# IMM100A register map
Vendor: Infineon; File version: 0.8.0 (Reference Manual v0.8.0)
CPU: CM0 r0p0, little endian, no MPU, no FPU, 2 interrupt priority bits
Registers are 32-bit, read-write, reset 0x0 unless marked. A register's access mark holds for its fields unless they carry their own. Offsets are from the block's base; [hi:lo] are bit positions; lines under a group give offsets from that group; {n}, {i} and the like mark numbered series; 'fields as' and 'values as' point back to an identical list.

## VADC — Analog to Digital Converter
Base 0x48030000
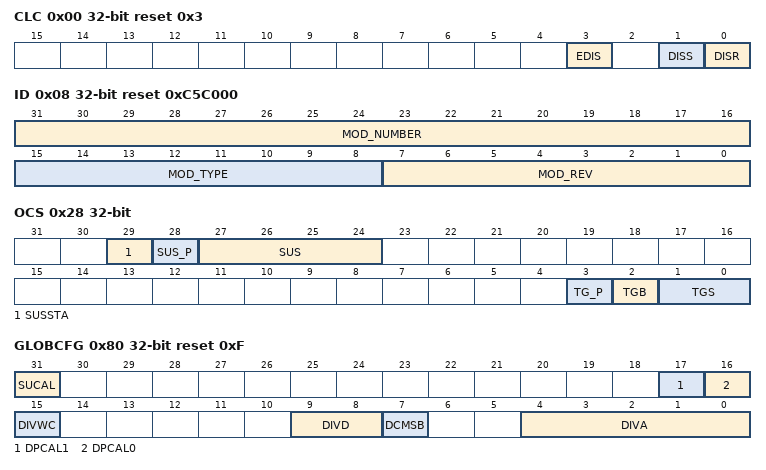
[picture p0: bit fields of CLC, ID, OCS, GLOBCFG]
0x00 CLC access per field reset 0x3 — Clock Control Register
  [3] EDIS rw — Sleep Mode Enable Control
    0=Sleep mode request is enabled and functional; 1=Module disregards the sleep mode control signal
  [1] DISS ro — Module Disable Status Bit
    0=Module clock is enabled; 1=Off: module is not clocked
  [0] DISR rw — Module Disable Request Bit
    0=On request: enable the module clock; 1=Off request: stop the module clock
0x08 ID ro reset 0xC5C000 (reset mask 0xFFFFFF00) — Module Identification Register
  [31:16] MOD_NUMBER — Module Number
  [15:8] MOD_TYPE — Module Type
  [7:0] MOD_REV — Module Revision
0x28 OCS access per field — OCDS Control and Status Register
  [29] SUSSTA ro — Suspend State
    0=Module is not (yet) suspended; 1=Module is suspended
  [28] SUS_P wo — SUS Write Protection
  [27:24] SUS rw — OCDS Suspend Control
    0=Will not suspend; 1=Hard suspend: Clock is switched off immediately; 2=Soft suspend mode 0: Stop conversions after the currently running one is completed and its result has been stored. No change for the arbiter.; 3=Soft suspend mode 1: Stop conversions after the currently running one is completed and its result has been stored. Stop arbiter after the current arbitration round.
  [3] TG_P wo — TGS, TGB Write Protection
  [2] TGB rw — OTGB0/1 Bus Select
    0=Trigger Set is output on OTGB0; 1=Trigger Set is output on OTGB1
  [1:0] TGS rw — Trigger Set for OTGB0/1
    0=No Trigger Set output; 1=Trigger Set 1: TS16_SSIG, input sample signals
0x80 GLOBCFG access per field reset 0xF — Global Configuration Register
  [31] SUCAL wo — Start-Up Calibration
    0=No action; 1=Initiate the start-up calibration phase (indication in bit GxARBCFG.CAL)
  [17] DPCAL1 rw — Disable Post-Calibration
    0=Automatic post-calibration after each conversion of group x; 1=No post-calibration
  [16] DPCAL0 rw — Disable Post-Calibration
    values as DPCAL1
  [15] DIVWC wo — Write Control for Divider Parameters
    0=No write access to divider parameters; 1=Bitfields DIVA, DCMSB, DIVD can be written
  [9:8] DIVD rw — Divider Factor for the Arbiter Clock
    0=fADCD = fADC; 1=fADCD = fADC / 2; 2=fADCD = fADC / 3; 3=fADCD = fADC / 4
  [7] DCMSB rw — Double Clock for the MSB Conversion
    0=1 clock cycle for the MSB (standard); 1=2 clock cycles for the MSB (fADCI > 20 MHz)
  [4:0] DIVA rw — Divider Factor for the Analog Internal Clock
    0=fADCI = fADC / 2; 1=fADCI = fADC / 2; 2=fADCI = fADC / 3; 31=fADCI = fADC / 32
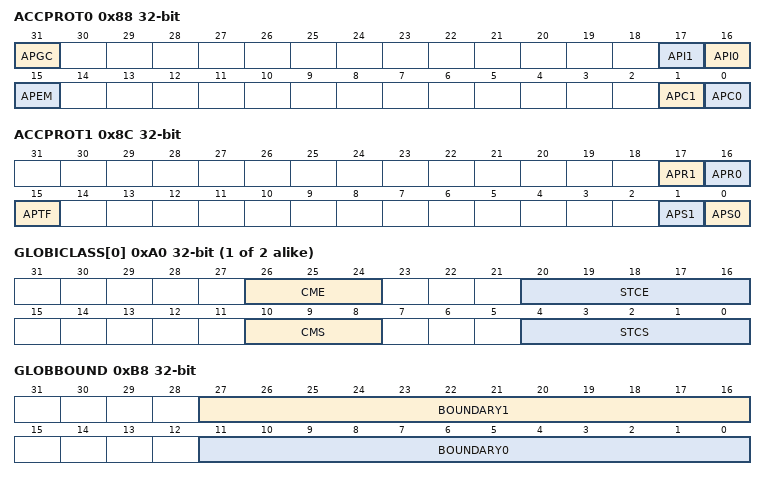
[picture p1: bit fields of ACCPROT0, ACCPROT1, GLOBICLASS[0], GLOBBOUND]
0x88 ACCPROT0 — Access Protection Register
  [31] APGC — Access Protection Global Configuration
    0=Full access to register; 1=Write access to global configuration register is blocked
  [17] API1 — Access Protection Initialization, Group 0 - 1
    0=Full access to registers; 1=Write access to initialization registers is blocked
  [16] API0 — Access Protection Initialization, Group 0 - 1
    values as API1
  [15] APEM — Access Protection External Multiplexer
    0=Full access to registers; 1=Write access to external multiplexer registers is blocked
  [1] APC1 — Access Protection Channel Control, Group 0 - 1
    0=Full access to registers; 1=Write access to channel control registers is blocked
  [0] APC0 — Access Protection Channel Control, Group 0 - 1
    values as APC1
0x8C ACCPROT1 — Access Protection Register
  [17] APR1 — Access Protection Result Registers, Group 0 - 1
    0=Full access to registers; 1=Write access to result registers is blocked
  [16] APR0 — Access Protection Result Registers, Group 0 - 1
    values as APR1
  [15] APTF — Access Protection Test Function
    0=Full access to register; 1=Write access to test function register is blocked
  [1] APS1 — Access Protection Service Request, Group 0 - 1
    0=Full access to registers; 1=Write access to service request registers is blocked
  [0] APS0 — Access Protection Service Request, Group 0 - 1
    values as APS1
{0xA0+4i} GLOBICLASS[{i}] (i=0..1) — Input Class Register, Global
  [26:24] CME — Conversion Mode for EMUX Conversions
    0=12-bit conversion; 1=10-bit conversion; 2=8-bit conversion; 5=10-bit fast compare mode
  [20:16] STCE — Sample Time Control for EMUX Conversions
  [10:8] CMS — Conversion Mode for Standard Conversions
    values as CME
  [4:0] STCS — Sample Time Control for Standard Conversions
0xB8 GLOBBOUND — Global Boundary Select Register
  [27:16] BOUNDARY1 — Boundary Value 1 for Limit Checking
  [11:0] BOUNDARY0 — Boundary Value 0 for Limit Checking
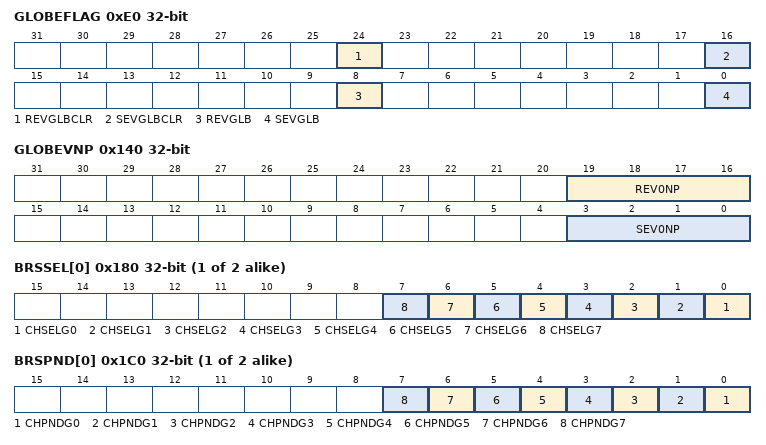
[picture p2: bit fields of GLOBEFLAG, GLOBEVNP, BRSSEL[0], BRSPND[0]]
0xE0 GLOBEFLAG access per field — Global Event Flag Register
  [24] REVGLBCLR wo — Clear Global Result Event
    0=No action; 1=Clear the result event flag REVGLB
  [16] SEVGLBCLR wo — Clear Source Event (Background)
    0=No action; 1=Clear the source event flag SEVGLB
  [8] REVGLB rw — Global Result Event
    0=No result event; 1=New result was stored in register GLOBRES
  [0] SEVGLB rw — Source Event (Background)
    0=No source event; 1=A source event has occurred
0x140 GLOBEVNP — Global Event Node Pointer Register
  [19:16] REV0NP — Service Request Node Pointer Global Result
    0=Select shared service request line 0 of common service request group 0; 3=Select shared service request line 3 of common service request group 0
  [3:0] SEV0NP — Service Request Node Pointer Backgr. Source
    values as REV0NP
{0x180+4i} BRSSEL[{i}] (i=0..1) — Background Request Source Channel Select Register
  [all] fields
    0=Ignore this channel; 1=This channel is part of the scan sequence
  [n] CHSELG{n} (n=0..7) — Channel Selection Group x
{0x1C0+4i} BRSPND[{i}] (i=0..1) — Background Request Source Pending Register
  [all] fields
    0=Ignore this channel; 1=Request conversion of this channel
  [n] CHPNDG{n} (n=0..7) — Channels Pending Group x
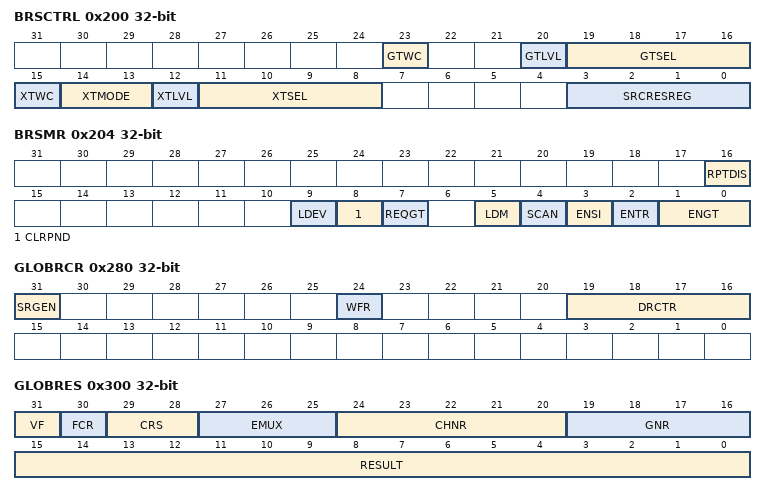
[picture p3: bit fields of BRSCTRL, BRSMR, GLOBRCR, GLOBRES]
0x200 BRSCTRL access per field — Background Request Source Control Register
  [23] GTWC wo — Write Control for Gate Configuration
    0=No write access to gate configuration; 1=Bitfield GTSEL can be written
  [20] GTLVL ro — Gate Input Level
  [19:16] GTSEL rw — Gate Input Selection
  [15] XTWC wo — Write Control for Trigger Configuration
    0=No write access to trigger configuration; 1=Bitfields XTMODE and XTSEL can be written
  [14:13] XTMODE rw — Trigger Operating Mode
    0=No external trigger; 1=Trigger event upon a falling edge; 2=Trigger event upon a rising edge; 3=Trigger event upon any edge
  [12] XTLVL ro — External Trigger Level
  [11:8] XTSEL rw — External Trigger Input Selection
  [3:0] SRCRESREG rw — Source-specific Result Register
    0=Use GxCHCTRy.RESREG to select a group result register; 1=Store result in group result register GxRES1; 15=Store result in group result register GxRES15
0x204 BRSMR access per field — Background Request Source Mode Register
  [16] RPTDIS rw — Repeat Disable
    0=A cancelled conversion is repeated; 1=A cancelled conversion is discarded
  [9] LDEV wo — Generate Load Event
    0=No action; 1=A load event is generated
  [8] CLRPND wo — Clear Pending Bits
    0=No action; 1=The bits in registers BRSPNDx are cleared
  [7] REQGT ro — Request Gate Level
    0=The gate input is low; 1=The gate input is high
  [5] LDM rw — Autoscan Source Load Event Mode
    0=Overwrite mode: Copy all bits from the select registers to the pending registers upon a load event; 1=Combine mode: Set all pending bits that are set in the select registers upon a load event (logic OR)
  [4] SCAN rw — Autoscan Enable
    0=No autoscan; 1=Autoscan functionality enabled: a request source event automatically generates a load event
  [3] ENSI rw — Enable Source Interrupt
    0=No request source interrupt; 1=A request source interrupt is generated upon a request source event (last pending conversion is finished)
  [2] ENTR rw — Enable External Trigger
    0=External trigger disabled; 1=The selected edge at the selected trigger input signal REQTR generates the load event
  [1:0] ENGT rw — Enable Gate
    0=No conversion requests are issued; 1=Conversion requests are issued if at least one pending bit is set; 2=Conversion requests are issued if at least one pending bit is set and REQGTx = 1; 3=Conversion requests are issued if at least one pending bit is set and REQGTx = 0
0x280 GLOBRCR — Global Result Control Register
  [31] SRGEN — Service Request Generation Enable
    0=No service request; 1=Service request after a result event
  [24] WFR — Wait-for-Read Mode Enable
    0=Overwrite mode; 1=Wait-for-read mode enabled for this register
  [19:16] DRCTR — Data Reduction Control
    0=Data reduction disabled
0x300 GLOBRES access per field read-has-side-effects — Global Result Register
  [31] VF rw — Valid Flag
    0=Read access: No new valid data available Write access: No effect; 1=Read access: Bitfield RESULT contains valid data and has not yet been read, or bit FCR has been updated Write access: Clear this valid flag and the data reduction counter (overrides a hardware set action)
  [30] FCR ro — Fast Compare Result
    0=Signal level was below compare value; 1=Signal level was above compare value
  [29:28] CRS ro — Converted Request Source
  [27:25] EMUX ro — External Multiplexer Setting
  [24:20] CHNR ro — Channel Number
  [19:16] GNR ro — Group Number
  [15:0] RESULT rw — Result of most recent conversion
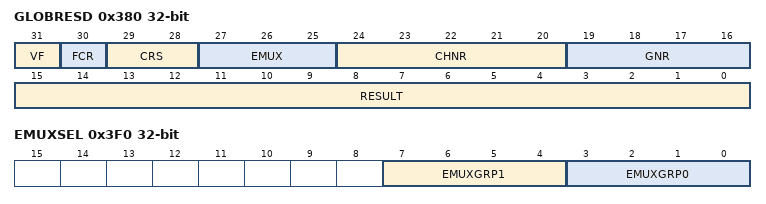
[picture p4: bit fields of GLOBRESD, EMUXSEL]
0x380 GLOBRESD access per field — Global Result Register, Debug
  fields as GLOBRES
0x3F0 EMUXSEL — External Multiplexer Select Register
  [7:4] EMUXGRP1 — External Multiplexer Group for Interface x
  [3:0] EMUXGRP0 — External Multiplexer Group for Interface x
